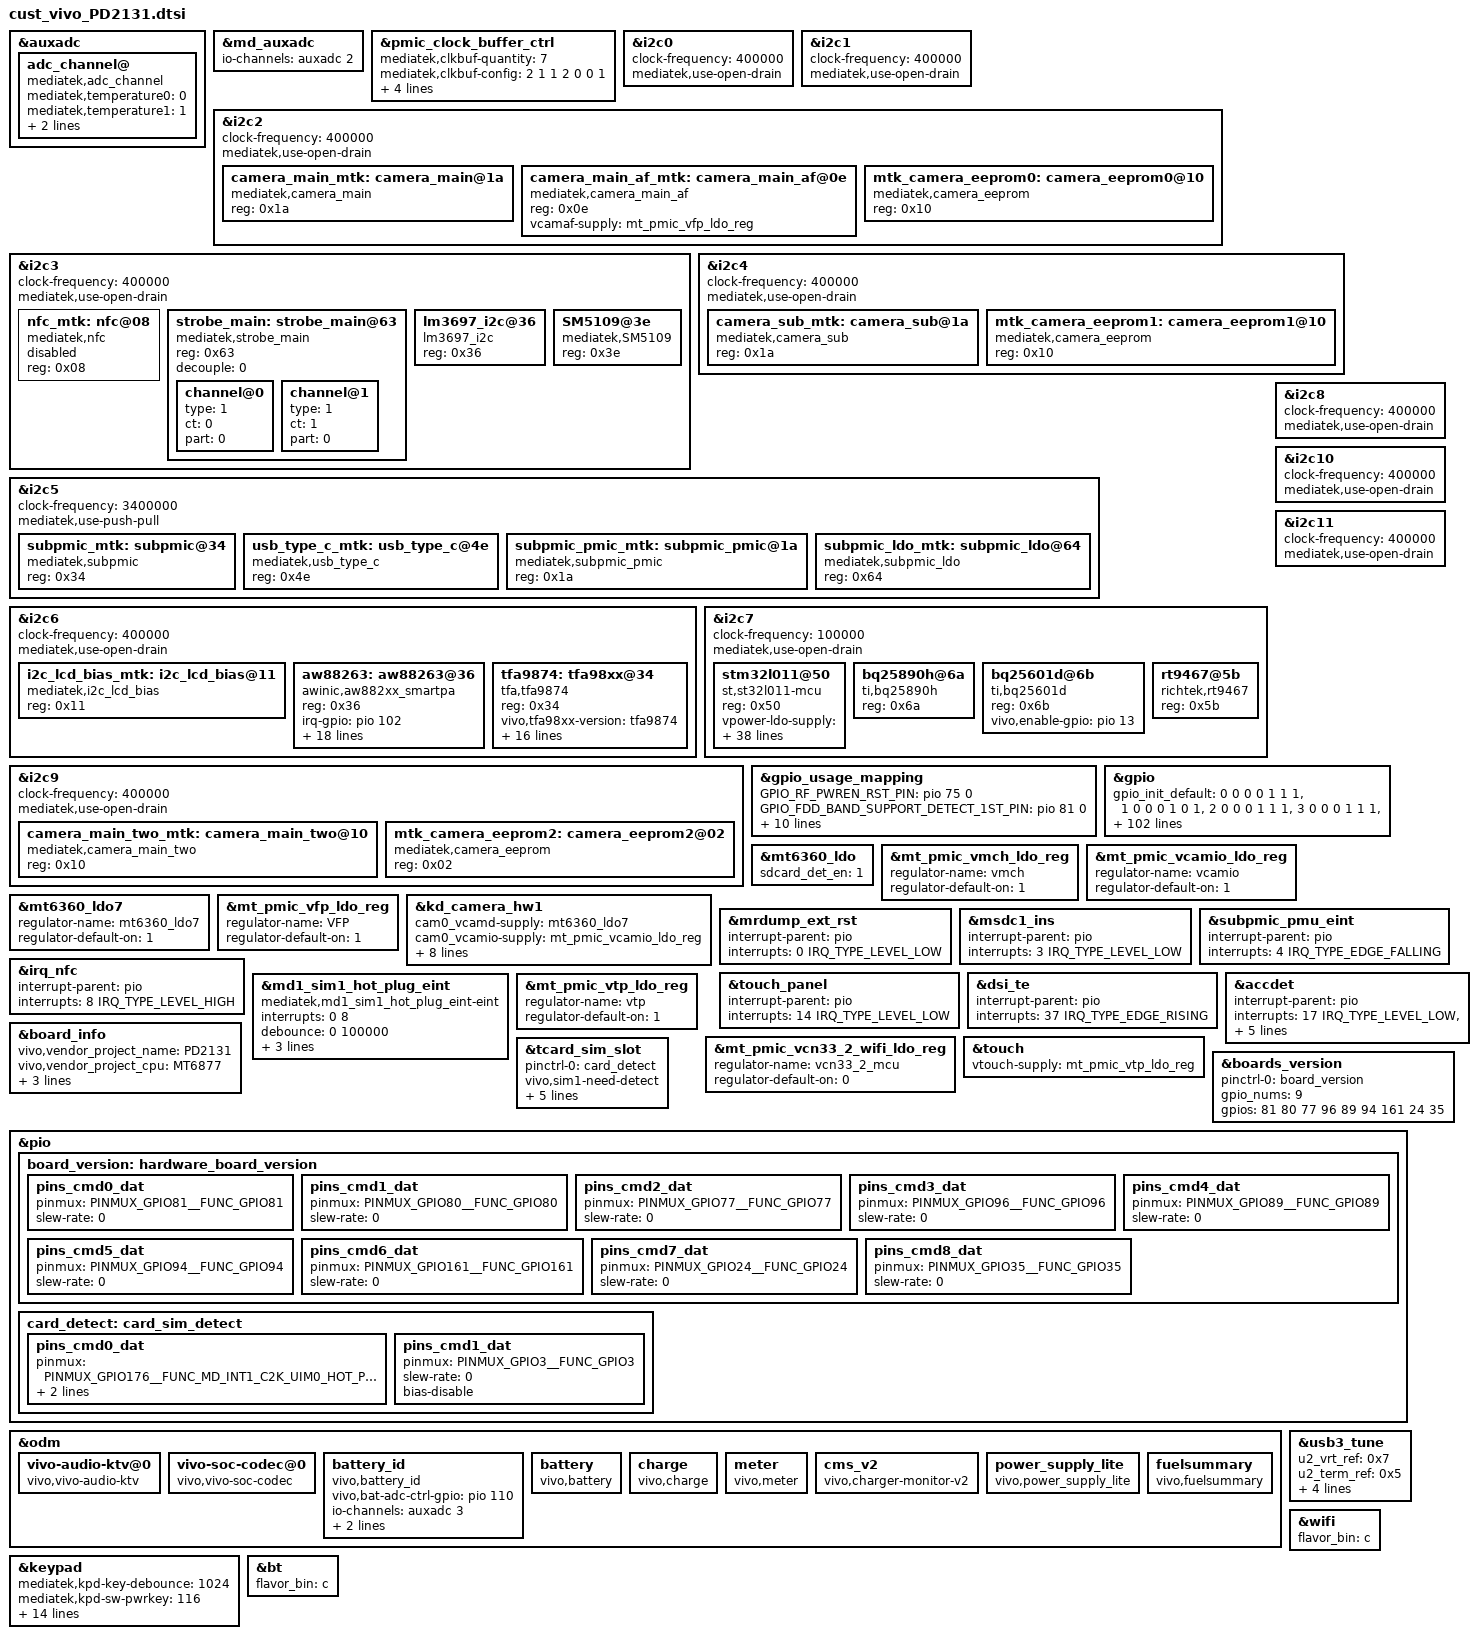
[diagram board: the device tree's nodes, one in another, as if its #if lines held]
/*
 * Generated by MTK SP DrvGen Version: 3.5.160809 for MT6877.
 * 2021-08-30 17:19:41
 * Do Not Modify The File.
 * Copyright Mediatek Inc. (c) 2016.
*/

/*************************
 * ADC DTSI File
*************************/

&auxadc {
	adc_channel@ {
		compatible = "mediatek,adc_channel";
		mediatek,temperature0 = <0>;
		mediatek,temperature1 = <1>;
		mediatek,adc_fdd_rf_params_dynamic_custom_ch = <2>;
		status = "okay";
	};
};
&md_auxadc {
	io-channels = <&auxadc 2>;
};


/*************************
 * CLK_BUF DTSI File
*************************/

&pmic_clock_buffer_ctrl {
	mediatek,clkbuf-quantity = <7>;
	mediatek,clkbuf-config = <2 1 1 2 0 0 1>;
	mediatek,clkbuf-output-impedance = <3 4 3 4 0 0 3>;
	mediatek,clkbuf-controls-for-desense = <0 4 0 4 0 0 0>;
	status = "okay";
};


/*************************
 * I2C DTSI File
*************************/

&i2c0 {
	#address-cells = <1>;
	#size-cells = <0>;
	clock-frequency = <400000>;
	mediatek,use-open-drain;
};

&i2c1 {
	#address-cells = <1>;
	#size-cells = <0>;
	clock-frequency = <400000>;
	mediatek,use-open-drain;
};

&i2c2 {
	#address-cells = <1>;
	#size-cells = <0>;
	clock-frequency = <400000>;
	mediatek,use-open-drain;
	camera_main_mtk:camera_main@1a {
		compatible = "mediatek,camera_main";
		reg = <0x1a>;
		status = "okay";
	};

	camera_main_af_mtk:camera_main_af@0e {
		compatible = "mediatek,camera_main_af";
		reg = <0x0e>;
		status = "okay";
	};
	mtk_camera_eeprom0:camera_eeprom0@10 {
		compatible = "mediatek,camera_eeprom";
		reg = <0x10>;
		status = "okay";
	};

};

&i2c3 {
	#address-cells = <1>;
	#size-cells = <0>;
	clock-frequency = <400000>;
	mediatek,use-open-drain;
	nfc_mtk:nfc@08 {
		compatible = "mediatek,nfc";
		reg = <0x08>;
		status = "disabled";
	};

	/*hope add for flashlight i2c device start*/
	strobe_main: strobe_main@63 {
		compatible = "mediatek,strobe_main";
		reg = <0x63>;
		status = "okay";
	};
	/*hope add for flashlight i2c device end*/

	lm3697_i2c@36 {
		compatible = "lm3697_i2c";
		reg = <0x36>;
		status = "okay";
	};
	SM5109@3e {
		compatible = "mediatek,SM5109";
		reg = <0x3e>;
		status = "okay";
	};
};

&i2c4 {
	#address-cells = <1>;
	#size-cells = <0>;
	clock-frequency = <400000>;
	mediatek,use-open-drain;
	camera_sub_mtk:camera_sub@1a {
		compatible = "mediatek,camera_sub";
		reg = <0x1a>;
		status = "okay";
	};

	mtk_camera_eeprom1:camera_eeprom1@10 {
		compatible = "mediatek,camera_eeprom";
		reg = <0x10>;
		status = "okay";
	};

};

&i2c5 {
	#address-cells = <1>;
	#size-cells = <0>;
	clock-frequency = <3400000>;
	mediatek,use-push-pull;
	subpmic_mtk:subpmic@34 {
		compatible = "mediatek,subpmic";
		reg = <0x34>;
		status = "okay";
	};

	usb_type_c_mtk:usb_type_c@4e {
		compatible = "mediatek,usb_type_c";
		reg = <0x4e>;
		status = "okay";
	};

	subpmic_pmic_mtk:subpmic_pmic@1a {
		compatible = "mediatek,subpmic_pmic";
		reg = <0x1a>;
		status = "okay";
	};

	subpmic_ldo_mtk:subpmic_ldo@64 {
		compatible = "mediatek,subpmic_ldo";
		reg = <0x64>;
		status = "okay";
	};

};

&i2c6 {
	#address-cells = <1>;
	#size-cells = <0>;
	clock-frequency = <400000>;
	mediatek,use-open-drain;
	i2c_lcd_bias_mtk:i2c_lcd_bias@11 {
		compatible = "mediatek,i2c_lcd_bias";
		reg = <0x11>;
		status = "okay";
	};

};

&i2c7 {
	#address-cells = <1>;
	#size-cells = <0>;
	clock-frequency = <400000>;
	mediatek,use-open-drain;
};

&i2c8 {
	#address-cells = <1>;
	#size-cells = <0>;
	clock-frequency = <400000>;
	mediatek,use-open-drain;
};

&i2c9 {
	#address-cells = <1>;
	#size-cells = <0>;
	clock-frequency = <400000>;
	mediatek,use-open-drain;

	camera_main_two_mtk:camera_main_two@10 {
		compatible = "mediatek,camera_main_two";
		reg = <0x10>;
		status = "okay";
	};
	mtk_camera_eeprom2:camera_eeprom2@02 {
		compatible = "mediatek,camera_eeprom";
		reg = <0x02>;
		status = "okay";
	};
};

&i2c10 {
	#address-cells = <1>;
	#size-cells = <0>;
	clock-frequency = <400000>;
	mediatek,use-open-drain;
};

&i2c11 {
	#address-cells = <1>;
	#size-cells = <0>;
	clock-frequency = <400000>;
	mediatek,use-open-drain;
};



/*************************
 * GPIO DTSI File
*************************/

&gpio_usage_mapping {
	GPIO_RF_PWREN_RST_PIN = <&pio 75 0>;
	GPIO_FDD_BAND_SUPPORT_DETECT_1ST_PIN = <&pio 81 0>;
	GPIO_FDD_BAND_SUPPORT_DETECT_2ND_PIN = <&pio 89 0>;
	GPIO_FDD_BAND_SUPPORT_DETECT_3RD_PIN = <&pio 161 0>;
	GPIO_SIM2_SIO = <&pio 170 0>;
	GPIO_SIM2_SCLK = <&pio 171 0>;
	GPIO_SIM2_SRST = <&pio 172 0>;
	GPIO_SIM1_SRST = <&pio 173 0>;
	GPIO_SIM1_SCLK = <&pio 174 0>;
	GPIO_SIM1_SIO = <&pio 175 0>;
	GPIO_SIM1_HOT_PLUG = <&pio 176 0>;
};

&gpio{
	gpio_init_default = <0 0 0 0 1 1 1>,
		<1 0 0 0 1 0 1>,
		<2 0 0 0 1 1 1>,
		<3 0 0 0 1 1 1>,
		<4 0 0 0 1 1 1>,
		<5 0 0 0 1 1 1>,
		<6 0 0 0 0 0 1>,
		<7 0 0 0 1 1 0>,
		<8 0 0 0 1 1 0>,
		<9 0 0 0 1 1 0>,
		<10 0 1 0 1 0 1>,
		<11 0 0 0 1 0 0>,
		<12 2 0 0 1 1 0>,
		<13 0 1 1 1 0 0>,
		<14 0 0 0 1 1 1>,
		<15 0 1 0 1 0 1>,
		<16 7 0 0 1 1 0>,
		<17 7 0 0 1 1 0>,
		<18 0 1 0 0 0 0>,
		<19 0 1 0 0 0 0>,
		<20 7 0 0 0 0 0>,
		<21 0 1 0 1 0 0>,
		<22 0 1 0 1 0 0>,
		<23 7 0 0 1 1 0>,
		<24 0 0 0 1 1 0>,
		<25 1 0 0 0 0 0>,
		<26 1 0 0 1 1 0>,
		<27 1 0 0 0 0 0>,
		<28 0 0 0 0 0 1>,
		<29 0 0 0 0 0 1>,
		<30 0 0 0 0 0 1>,
		<31 0 0 0 0 0 1>,
		<32 1 0 0 1 1 0>,
		<33 1 0 0 1 1 0>,
		<34 1 0 0 1 1 0>,
		<35 0 0 0 1 1 0>,
		<36 1 0 0 1 1 1>,
		<37 1 0 0 1 1 1>,
		<38 1 0 0 1 1 1>,
		<39 1 0 0 1 0 1>,
		<40 0 1 0 1 0 1>,
		<41 1 0 0 0 0 1>,
		<42 1 0 0 0 0 1>,
		<43 1 0 0 1 0 1>,
		<44 1 0 0 1 0 1>,
		<45 1 0 0 1 1 1>,
		<46 1 0 0 0 0 0>,
		<47 1 0 0 0 0 0>,
		<48 1 0 0 0 0 0>,
		<49 1 0 0 0 0 0>,
		<50 1 0 0 1 0 0>,
		<51 1 0 0 1 0 0>,
		<52 1 0 0 1 0 0>,
		<53 1 0 0 1 0 0>,
		<54 1 0 0 1 0 1>,
		<55 1 0 0 1 0 0>,
		<56 1 0 0 1 0 0>,
		<57 1 0 0 1 0 0>,
		<58 1 0 0 1 0 0>,
		<59 1 0 0 1 0 0>,
		<60 1 0 0 0 0 1>,
		<61 1 0 0 0 0 1>,
		<62 1 0 0 0 0 1>,
		<63 1 0 0 0 0 1>,
		<64 1 0 0 1 1 1>,
		<65 1 0 0 1 1 1>,
		<66 1 0 0 1 0 1>,
		<67 1 0 0 1 0 1>,
		<68 1 0 0 0 0 0>,
		<69 1 0 0 1 0 0>,
		<70 1 0 0 1 0 1>,
		<71 1 0 0 0 0 1>,
		<72 1 0 0 0 0 1>,
		<73 1 0 0 0 0 1>,
		<74 1 0 0 0 0 1>,
		<75 0 1 1 1 0 1>,
		<76 1 0 0 0 0 1>,
		<77 0 0 0 1 1 0>,
		<78 1 0 0 0 0 1>,
		<79 1 0 0 0 0 1>,
		<80 0 0 0 1 1 0>,
		<81 0 0 0 1 1 0>,
		<82 1 0 0 0 0 0>,
		<83 1 0 0 1 0 0>,
		<84 1 0 0 0 0 0>,
		<85 1 0 0 1 0 0>,
		<86 1 0 0 1 0 1>,
		<87 1 0 0 0 0 1>,
		<88 1 0 0 0 0 1>,
		<89 0 0 0 1 1 0>,
		<90 1 0 0 0 0 1>,
		<91 1 0 0 0 0 1>,
		<92 1 0 0 0 0 1>,
		<93 1 0 0 0 0 1>,
		<94 0 0 0 1 1 0>,
		<95 1 0 0 0 0 1>,
		<96 0 0 0 1 1 0>,
		<97 1 0 0 0 0 1>,
		<98 0 1 0 0 0 1>,
		<99 0 1 0 0 0 1>,
		<100 0 1 0 0 0 1>,
		<101 0 1 0 0 0 1>,
		<102 1 0 0 1 1 0>,
		<103 1 0 0 1 1 0>,
		<104 1 0 0 1 1 0>,
		<105 1 0 0 1 1 0>,
		<106 1 0 0 1 1 0>,
		<107 0 1 1 1 0 1>,
		<108 0 1 0 1 0 1>,
		<109 0 1 0 1 0 0>,
		<110 0 1 0 1 0 0>,
		<111 0 1 0 1 0 0>,
		<112 1 0 0 1 1 0>,
		<113 0 0 0 1 1 0>,
		<114 0 0 0 1 1 0>,
		<115 0 1 1 1 0 0>,
		<116 1 0 0 1 1 1>,
		<117 0 0 0 1 1 0>,
		<118 0 0 0 1 1 0>,
		<119 0 0 0 1 1 0>,
		<120 1 0 0 1 1 0>,
		<121 0 0 0 1 1 0>,
		<122 7 0 0 1 1 1>,
		<123 7 0 0 1 1 0>,
		<124 7 0 0 1 1 0>,
		<125 7 0 0 1 1 0>,
		<126 2 0 0 1 0 0>,
		<127 2 0 0 1 0 0>,
		<128 2 0 0 1 1 1>,
		<129 2 0 0 1 0 1>,
		<130 2 0 0 1 1 1>,
		<131 2 0 0 1 1 1>,
		<132 1 0 0 1 1 1>,
		<133 1 0 0 1 1 1>,
		<134 1 0 0 1 1 1>,
		<135 1 0 0 1 1 1>,
		<136 1 0 0 1 1 1>,
		<137 1 0 0 1 1 1>,
		<138 4 0 0 1 1 0>,
		<139 4 0 0 1 1 0>,
		<140 0 1 0 1 0 1>,
		<141 0 1 0 1 0 1>,
		<142 0 1 0 1 0 0>,
		<143 1 0 0 1 1 1>,
		<144 1 0 0 1 1 1>,
		<145 1 0 0 1 1 1>,
		<146 1 0 0 1 1 1>,
		<147 1 0 0 1 1 1>,
		<148 1 0 0 1 1 1>,
		<149 0 1 0 0 0 0>,
		<150 0 1 0 0 0 0>,
		<151 1 0 0 1 1 0>,
		<152 0 1 0 0 0 0>,
		<153 0 0 0 1 1 0>,
		<154 0 1 0 0 0 0>,
		<155 0 1 0 0 0 0>,
		<156 0 0 0 1 1 0>,
		<157 0 1 0 0 0 0>,
		<158 0 0 0 1 1 0>,
		<159 0 0 0 1 1 0>,
		<160 0 1 0 0 0 0>,
		<161 0 0 0 1 1 0>,
		<162 0 0 0 1 1 0>,
		<163 0 1 0 0 0 0>,
		<164 1 0 0 1 1 0>,
		<165 1 0 0 0 0 0>,
		<166 1 0 0 1 1 0>,
		<167 1 0 0 1 1 0>,
		<168 1 0 0 1 1 0>,
		<169 1 0 0 1 1 0>,
		<170 1 0 0 1 1 1>,
		<171 1 0 0 0 0 1>,
		<172 1 0 0 0 0 1>,
		<173 1 0 0 0 0 1>,
		<174 1 0 0 0 0 1>,
		<175 1 0 0 1 1 1>,
		<176 1 0 0 0 0 1>,
		<177 0 0 0 0 0 1>,
		<178 1 0 0 1 0 0>,
		<179 1 0 0 1 0 0>,
		<180 1 0 0 1 1 1>,
		<181 1 0 0 1 1 1>,
		<182 1 0 0 1 1 0>,
		<183 1 0 0 1 1 0>,
		<184 1 0 0 0 0 0>,
		<185 1 0 0 0 0 0>,
		<186 1 0 0 1 1 1>,
		<187 1 0 0 1 1 1>,
		<188 0 1 0 1 1 0>,
		<189 0 1 0 1 1 0>,
		<190 1 0 0 1 1 0>,
		<191 1 0 0 1 1 0>,
		<192 1 0 0 1 1 0>,
		<193 0 0 0 1 1 0>,
		<194 0 0 0 1 1 0>,
		<195 0 0 0 1 1 0>,
		<196 0 0 0 1 0 0>,
		<197 0 0 0 1 0 0>,
		<198 0 0 0 1 0 0>,
		<199 0 0 0 1 0 0>,
		<200 0 0 0 1 0 0>,
		<201 0 0 0 1 0 0>,
		<202 0 0 0 1 0 0>,
		<203 0 0 0 1 0 0>,
		<204 0 0 0 1 0 0>,
		<205 0 0 0 1 0 0>,
		<206 0 0 0 1 0 0>,
		<207 0 0 0 1 0 0>,
		<208 0 0 0 1 0 0>;
};


/* yangtao add for tf start */
&mt6360_ldo {
	sdcard_det_en = <1>; /* enable tf */
};
/* yangtao add for tf end */

&mt_pmic_vmch_ldo_reg {
	regulator-name = "vmch";
	regulator-default-on = <1>; /* 0:skip, 1: off, 2:on */
	status = "okay";
};

&mt_pmic_vcamio_ldo_reg {
	regulator-name = "vcamio";
	regulator-default-on = <1>; /* 0:skip, 1: off, 2:on */
	status = "okay";
};


&mt6360_ldo7 {
	regulator-name = "mt6360_ldo7";
	regulator-default-on = <1>; /* 0:skip, 1: off, 2:on */
	status = "okay";
};

&mt_pmic_vfp_ldo_reg {
	regulator-name = "VFP";
	regulator-default-on = <1>; /* 0:skip, 1: off, 2:on */
	status = "okay";
};


&kd_camera_hw1 {
	cam0_vcamd-supply = <&mt6360_ldo7>;
	cam0_vcamio-supply = <&mt_pmic_vcamio_ldo_reg>;		
	cam1_vcamio-supply = <&mt_pmic_vcamio_ldo_reg>;
	cam2_vcamio-supply = <&mt_pmic_vcamio_ldo_reg>;
	
	cam0_enable_sensor = "s5kjn1sq03pd2131_mipi_raw s5kgw3sp13pd2123_mipi_raw";
	cam1_enable_sensor = "imx355pd2131_mipi_raw s5k3p9sppd2123_mipi_raw";
        cam2_enable_sensor = "ov02b10pd2131_mipi_raw";
	
	status = "okay";
};


/*lishuo add main af pmic power start*/
&camera_main_af_mtk {
	vcamaf-supply = <&mt_pmic_vfp_ldo_reg>;
};
/*lishuo add main af pmic power end*/


/*hope add for flashlight channel start*/
&strobe_main {
	decouple = <0>;
	channel@0 {
		type = <1>;
		ct = <0>;
		part = <0>;
	};
	channel@1 {
		type = <1>;
		ct = <1>;
		part = <0>;
	};
};
/*hope add for flashlight channel end*/

/*************************
 * EINT DTSI File
*************************/

#include <dt-bindings/interrupt-controller/irq.h>
#include <dt-bindings/interrupt-controller/arm-gic.h>

&mrdump_ext_rst {
	interrupt-parent = <&pio>;
	interrupts = <0 IRQ_TYPE_LEVEL_LOW>;
	status = "okay";
};

&msdc1_ins {
	interrupt-parent = <&pio>;
	interrupts = <3 IRQ_TYPE_LEVEL_LOW>;
	status = "okay";
};

&subpmic_pmu_eint {
	interrupt-parent = <&pio>;
	interrupts = <4 IRQ_TYPE_EDGE_FALLING>;
	status = "okay";
};

&irq_nfc {
	interrupt-parent = <&pio>;
	interrupts = <8 IRQ_TYPE_LEVEL_HIGH>;
	status = "okay";
};

&touch_panel {
	interrupt-parent = <&pio>;
	interrupts = <14 IRQ_TYPE_LEVEL_LOW>;
	status = "okay";
};

&dsi_te {
	interrupt-parent = <&pio>;
	interrupts = <37 IRQ_TYPE_EDGE_RISING>;
	status = "okay";
};

&accdet {
	interrupt-parent = <&pio>;
	interrupts = <17 IRQ_TYPE_LEVEL_LOW>,
					<16 IRQ_TYPE_LEVEL_LOW>;
	deb-gpios = <&pio 17 0>;
	deb-rgpios = <&pio 16 0>;
	debounce = <256000>;
	debounce1 = <256000>;
	status = "okay";
};



/*************************
 * MD1_EINT DTSI File
*************************/

&md1_sim1_hot_plug_eint {
	compatible = "mediatek,md1_sim1_hot_plug_eint-eint";
	interrupts = <0 8>;
	debounce = <0 100000>;
	dedicated = <0 0>;
	src_pin = <0 1>;
	sockettype = <0 0>;
	status = "okay";
};




/*************************
 * PMIC DTSI File
*************************/

&mt_pmic_vcamio_ldo_reg {
	regulator-name = "vcamio";
	regulator-default-on = <1>; /* 0:skip, 1: off, 2:on */
	status = "okay";
};
&mt_pmic_vtp_ldo_reg {
	regulator-name = "vtp";
	regulator-default-on = <1>; /* 0:skip, 1: off, 2:on */
	status = "okay";
};

&kd_camera_hw1 {
	vcamio-supply = <&mt_pmic_vcamio_ldo_reg>;
	status = "okay";
};

&mt_pmic_vcn33_2_wifi_ldo_reg {
	regulator-name = "vcn33_2_mcu";
	regulator-default-on = <0>;
	status = "okay";
};
&touch {
	vtouch-supply = <&mt_pmic_vtp_ldo_reg>;
	status = "okay";
};

/* add board info fdt node by corebsp begin */
&board_info {
	vivo,vendor_project_name = "PD2131";
	vivo,vendor_project_cpu = "MT6877";
	vivo,vendor_cpu_set = "Dimensity_900";
	vivo,vendor_project_freq = "2.4";
	vivo,vendor_project_cpunum = <8>;
};

&boards_version {
	pinctrl-names = "default";
	pinctrl-0 = <&board_version>;
	gpio_nums = <9>;
	gpios = <81 80 77 96 89 94 161 24 35>;
	/* if use pcb version,need to define:pcb_gpio_nums pcb_gpios pcb_maps_nums pcb_gpios_maps */
	/*pcb_gpio_nums = <2>;*/
	/*pcb_gpios = <107 108>;*/
	/* 00:MP_0.1, 01:MP_0.2, 10:MP_0.3, 11:MP_0.4 */
	/*pcb_maps_nums = <8>;*/
	/*pcb_gpios_maps = <0x0 0x1 0x1 0x2 0x2 0x3 0x3 0x4>;*/

};

&tcard_sim_slot {
	pinctrl-names = "default";
	pinctrl-0 = <&card_detect>;
	vivo,sim1-need-detect;
	vivo,sim2-need-detect;
	vivo,sim1-detect-high;
	vivo,sim2-detect-high;

	card-detect-sim1,gpios = <&pio 176 0x0>;
	card-detect-sim2,gpios = <&pio 176 0x0>;
};

&pio {
	board_version: hardware_board_version {
		pins_cmd0_dat {
			pinmux = <PINMUX_GPIO81__FUNC_GPIO81>;
			slew-rate = <0>;
		};
		pins_cmd1_dat {
			pinmux = <PINMUX_GPIO80__FUNC_GPIO80>;
			slew-rate = <0>;
		};
		pins_cmd2_dat {
			pinmux = <PINMUX_GPIO77__FUNC_GPIO77>;
			slew-rate = <0>;
		};
		pins_cmd3_dat {
			pinmux = <PINMUX_GPIO96__FUNC_GPIO96>;
			slew-rate = <0>;
		};
		pins_cmd4_dat {
			pinmux = <PINMUX_GPIO89__FUNC_GPIO89>;
			slew-rate = <0>;
		};
		pins_cmd5_dat {
			pinmux = <PINMUX_GPIO94__FUNC_GPIO94>;
			slew-rate = <0>;
		};
		pins_cmd6_dat {
			pinmux = <PINMUX_GPIO161__FUNC_GPIO161>;
			slew-rate = <0>;
		};
		pins_cmd7_dat {
			pinmux = <PINMUX_GPIO24__FUNC_GPIO24>;
			slew-rate = <0>;
		};
		pins_cmd8_dat {
			pinmux = <PINMUX_GPIO35__FUNC_GPIO35>;
			slew-rate = <0>;
		};
	};

	card_detect: card_sim_detect {
		pins_cmd0_dat {
			pinmux = <PINMUX_GPIO176__FUNC_MD_INT1_C2K_UIM0_HOT_PLUG>;
			slew-rate = <0>;
			bias-disable;
		};
		pins_cmd1_dat {
			pinmux = <PINMUX_GPIO3__FUNC_GPIO3>;
			slew-rate = <0>;
			bias-disable;
		};
	};
};
/* add board info fdt node by corebsp end */


/*************************
 * POWER DTSI File
*************************/



/*************************
 * qinbaoqiang add for audio start
**************************/
&odm {
	vivo-audio-ktv@0 {
		compatible = "vivo,vivo-audio-ktv";
		status = "okay";
	};
	
	vivo-soc-codec@0 {
		compatible = "vivo,vivo-soc-codec";
		status = "okay";
	};
/*	
	typec_switch:typecswitch {
		compatible = "vivo,typec-switch";
		interrupt-parent = <&pio>;
		interrupts = <17 IRQ_TYPE_LEVEL_LOW 17 0>;
		deb-gpios = <&pio 17 0>;
		debounce = <256000>;
		pinctrl-names = "default", "typec_eint_as_int";
		pinctrl-0 = <&typec_pins_default>;
		pinctrl-1 = <&typec_eint_as_int>;
		status = "okay";
	};	*/
};
/*
&pio {
	typec_pins_default: typecdefault {
	};
	typec_eint_as_int: typeceint@0 {
		pins_cmd_dat {
			pinmux = <PINMUX_GPIO17__FUNC_GPIO17>;
			slew-rate = <0>;
			bias-pull-up;
			input-enable;
		};
	};
};*/

&i2c6{
/*
	tas2562:tas2562@4c {
		compatible = "ti,tas2562";
		reg = <0x4c>;
		ti,left-channel = <0x4c>;
		ti,channels = <1>; *//* channel number */
/*		ti,reset-gpio = <&pio 111 0>;
		ti,irq-gpio = <&pio 102 0>;

		vivo,impedance-min = <3145728>;*/ /*speaker min impedance 6.0ohm*/
/*		vivo,impedance-max = <5242880>; *//*speaker max impedance 10.0ohm*/
/*		vivo,frequency-min = <400>;
		vivo,frequency-max = <920>;
		vivo,Qt-min = <100>;
		status = "okay";
    };
*/
	aw88263:aw88263@36 {
		/* AWINIC AW88263 mono SmartPA */
		compatible = "awinic,aw882xx_smartpa";
		reg = <0x36>;
		irq-gpio = <&pio 102 0>;
		reset-gpio = <&pio 111 0>;
		monitor-flag = <1>;

		/*archer fix for replace aw protection algorithm with vivo algorithm,because vivo algorithm will read smartamp.bin,but it's awinic ctreate*/
		vivo-replace-protect-algo;

		aw-cali-mode = "aw_debugfs"; //aw_misc or aw_debugfs
		vivo,impedance-min = <2621440>; /*speaker min impedance 5.0ohm*/
		vivo,impedance-max = <5242880>; /*speaker max impedance 10.0ohm*/
		vivo,frequency-min = <500>;
		vivo,frequency-max = <950>;
		vivo,Qt-min = <110>;

		vivo,Impedance-Min-L15 = <163840>; /* 5*2^15 */
		vivo,Impedance-Max-L15 = <327680>; /* 10*2^15 */
		vivo,Frequency-Min-L15 = <16384000>; /* 500*2^15 */
		vivo,Frequency-Max-L15 = <32768000>; /* 1000*2^15 */
		vivo,Qt-Min-L15 = <32768>;  /* 1*2^15 */
		vivo,VendorID = <63>;       /* AW88263 */
		vivo,V-Max-L15 = <589824>;  /* 18*2^15 */
		vivo,I-Max-L15 = <120259>;  /* 3.67*2^15 */
		vivo,Vout-Max-L15 = <262144>; /* 8*2^15 */

		status = "okay";
	};
	tfa9874: tfa98xx@34 {
		status = "okay";
		compatible = "tfa,tfa9874";
		#sound-dai-cells = <1>;
		reg = <0x34>;
		vivo,tfa98xx-version = "tfa9874";
		vivo,tfa98xx-config = "tfa98xx_PD2131.cnt";
		vivo,tfa98xx-impedance-min = <6000>;
		vivo,tfa98xx-impedance-max = <10000>;
		vivo,tfa98xx-frequency-min = <600>;
		vivo,tfa98xx-frequency-max = <900>;
		vivo,tfa98xx-Qt-min = <110>;
		reset-gpio = <&pio 111 0>;

		vivo,Impedance-Min-L15 = <163840>; /* 5*2^15 */
		vivo,Impedance-Max-L15 = <327680>; /* 10*2^15 */
		vivo,Frequency-Min-L15 = <16384000>; /* 500*2^15 */
		vivo,Frequency-Max-L15 = <32768000>; /* 1000*2^15 */
		vivo,Qt-Min-L15 = <32768>;  /* 1*2^15 */
		vivo,VendorID = <74>;       /* NXP9874 */
		vivo,V-Max-L15 = <747111>;  /* 22.8*2^15 */
		vivo,I-Max-L15 = <109118>;  /* 3.33*2^15 */
		vivo,Vout-Max-L15 = <327680>; /* 10*2^15 */
	};
};
/*  qinbaoqiang add end */

/*
	{TI_SMART_PA, (14<<15)458752, (2<<15)65536, 260506}
	{NXP_SMART_PA, 747111, 109118, 327680}
	{AW_SMART_PA, (18<<15), 120259, 262144}
*/

/* fuxi add for battery&charge start */
#ifdef CONFIG_VIVO_CHARGING_NEW_ARCH
#ifdef CONFIG_VIVO_CHARGING_DTS_MOVE_HEAD_FILE
&odm {
	battery_id {
		compatible = "vivo,battery_id";
		status = "okay";

		vivo,bat-adc-ctrl-gpio = <&pio 110 0>;

		io-channels = <&auxadc 3>;
		io-channel-names = "battery_id_adc";

		vivo,bat-name = "B-N8 ATL 3920","B-G7 SX 5000","B-G7 ATL 5000","UNKNOWN";
	};

	battery: battery {
		compatible = "vivo,battery";
		status = "okay";
	};

	charge: charge {
		compatible = "vivo,charge";
		status = "okay";
	};

	meter: meter {
		compatible = "vivo,meter";
		status = "okay";
	};

	cms_v2: cms_v2 {
		compatible = "vivo,charger-monitor-v2";
		status = "okay";
	};

	power_supply_lite: power_supply_lite {
		compatible = "vivo,power_supply_lite";
		status = "okay";
	};

	fuelsummary: fuelsummary {
		compatible = "vivo,fuelsummary";
		status = "okay";
	};
};

#else

&battery_id {
	status = "okay";
	compatible = "vivo,battery_id";

	vivo,bat-adc-ctrl-gpio = <&pio 110 0>;

	io-channels = <&auxadc 3>;
	io-channel-names = "battery_id_adc";

	vivo,bat-name = "UNKNOWN","B-R3 AT DS 5000","B-Q7 AT NV 5000";
};

&battery {
	status = "okay";
	compatible = "vivo,battery";

	io-channels = <&auxadc 0>,
		<&auxadc 4>;
	io-channel-names = "primary_board_therm",
		"parallel_board_therm";

	vivo,low-volt-threshold = <3400>;
	vivo,soft-rise-percent = <96>;
	vivo,soft-rise-cumulative = <3>;
	vivo,soft-rise-keep-cumulative = <10>;
	vivo,percnet-sync-delta = <5>;
	vivo,percnet-sync-cumulative = <9>;
	vivo,full-sync-cumulative = <3>;
	vivo,soft-term-percent = <99>;
	vivo,soft-term-cumulative = <36>;
};

&charge {
	status = "okay";
	compatible = "vivo,charge";

	vivo,chg-wdt-s = <40>;
	vivo,re-chg-voltage-mv = <100>;
	vivo,prechg-voltage-mv = <3000>;
	vivo,iprechg-current-ma = <300>;
	vivo,iterm-current-ma = <256>;
	vivo,vreg-voltage-mv = <4430>;
	vivo,vindpm-voltage-mv = <4600>;
	vivo,sys-voltage-min-mv= <3300>;
	vivo,boostv-voltage-mv = <5150>;
	vivo,boostv-ilimit-ma = <1300>;
	vivo,ovp-voltage-mv = <15000>;

	/*
	 * 0  auto detect charging
	 * 1  vivo-normal chargine
	 * 2  vivo-single engine charging
	 * 3  vivo-dual engine charging
	 * 4  vivo-flash charging
	 */
	vivo,charge-scheme = <0>;
	vivo,direct-charger-enable;

	/*
	 * SUPPORTED_ADAPTER_DEFAULT = 0,
	 * SUPPORTED_ADAPTER_VIVO_LV_DCHG_5V_4500MA = 1,
	 * SUPPORTED_ADAPTER_VIVO_HV_DCHG_10V_2250MA = 2,
	 * SUPPORTED_ADAPTER_QC20__9V_2000MA = 3,
	 * SUPPORTED_ADAPTER_VIVO_HV_DCHG_10V_4000MA = 4,
	 * SUPPORTED_ADAPTER_MAX,
	 */
	vivo,supported-adapter = <3>;

	//parameter for 9V2A
	vivo,primary-ichg-max-ma = <2240>;
	vivo,parallel-ichg-max-ma = <1680>;

	vivo,flashchg-spec-ma = <2000 4500 8200>;
	vivo,fastchg-spec-ma = <2000 2100 3800>;
	vivo,normalchg-spec-ma = <2000 1500 2300>;

	/* 0---PMIC; 1---CHGIC */
	vivo,vbus-detect-source = <1>;

	//vivo,usboe-gpio = <&pio 163 0>;

	/*ffc*/
	//vivo,ffc-enable;
	vivo,ffc-iterm-ma = <(-750)>;
	vivo,ffc-vreg-mv = <4500>;
	vivo,ffc-temperature-range = <150 450>;
	vivo,ffc-full-vbat-table-size = <3>;
	vivo,ffc-full-vbat-table = <4480 4480 4440>;
	vivo,ffc-full-ibat-table-size = <3>;
	vivo,ffc-full-ibat-table = <150 199 (-858)>,
		<200 349 (-1127)>,
		<350 449 (-1274)>;
};

&meter {
	status = "okay";
	compatible = "vivo,meter";

	vivo,load-capacity-delta-max = <60>;
	vivo,poweron-delta-capacity = <20>;
	vivo,poweron-low-capacity = <3>;
	vivo,volt-car-delta = <8>;
	vivo,car-volt-delta = <6>;
	vivo,meter-res-compesate = <10>;
	vivo,ocv-board-compesate = <0>;

	/* 0---AGING_UNSUPPORTED; 1---DRIVER_SUPPORTED; 2---USPACE_SUPPORTED */
	vivo,battery-aging-support = <2>;

	vivo,capacity-mAh = <4880>;
	/*COLD_CHG COLD_DISCHG NORMAL_CHG NORMAL_DISCHG*/
	vivo,car-tune-value = <980 1010 1000 1010>,
		<980 1010 1000 1010>,
		<1000 1000 1000 1000>,
		<1000 1000 1000 1000>,
		<1000 1000 1000 1000>,
		<1000 1000 1000 1000>;
	vivo,bats-qmax = <4060 4280 4400 4640 4750>,
		<4060 4280 4400 4640 4750>,
		<4240 4480 4770 4850 4880>,
		<4611 4630 4747 4805 4786>,
		<4611 4630 4747 4805 4786>,
		<4611 4630 4747 4805 4786>;
	#include "bat_setting/PD2123_battery_table.dtsi"
	/* car-tune adjust remap */
	vivo,car-tune-adjust-enable;
	vivo,car-tune-adjust-size = <3>;
	vivo,car-tune-adjust-table = <0 10 (355) 7>,
		<11 20 (-30) 9>,
		<21 100 (-30) 12>;
};

&cms_v2 {
	compatible = "vivo,charger-monitor-v2";
	status = "okay";

	default_board: single_charger_board {
		       /*default board: keep in xxxxxx*/
		       support-board-version = "xxxxxx";

		       vivo,bat-det-method = <0>;//r:0, rc:1, eprom:2, ex-fg:3
		       vivo,bat-id-gpio = <&pio 110 0>;

		       /*
			  CHG0__CHARGING_TECHNOLOGY_NONE = 0,
			  CHG1__NORMAL_CHARGING,			//5V/2A normal charging
			  CHG2__QC2_CHARGING,				//9V/2A	QC2.0 charging
			  CHG3__LOW_VOLTAGE_DIRECT_CHARGING,		//5V/4.5A direct charging
			  CHG4__SINGLE_IC_DIV2_CHARGING,		//single IC Div/2 charging
			  CHG5__DUAL_IC_DIV2_CHARGING,			//Dual IC Div/2 charging
			  CHG6__DUAL_IC_DUAL_BATTERY_DIV2_CHARGING,	//Dual IC Div/2 charging
			  CHGX__CHARGING_TECHNOLOGY_MAX,
			*/
		       //vivo,charging-technology = <2>;

		       //vivo,no-bat-warning;
		       //vivo,no-chg-timeout;
		       vivo,chg-timeout-mins = <900>;

		       //high temperature charger current control enable
		       vivo,htccc-enable;
		       vivo,htccc-data = <46 55 4100000 100000>;

		       //vivo,fbon-scale-enable;/*disable default*/
		       vivo,fbon-scale-data = <2 100 100>;

		       //vivo,switch-scale-enable;/*disable from rom4.0*/
		       vivo,switch-scale-data = <75 53>;

		       vivo,calling-scale-enable;
		       vivo,calling-scale-data = <100 38>;/*ibat:3900 * 0.54 = 2106,more than 1500,not exit dchg*/
		       vivo,calling-dchg-disable;

		       vivo,weixin-calling-scale-enable;
		       vivo,weixin-calling-scale-data = <100 104>;/*4200mA*/

		       vivo,carlife-scale-enable;
		       vivo,carlife-scale-data = <100 12>;/*500mA*/

		       //vivo,fixed-scale-enable;
		       vivo,fixed-scale-data = <120 3800 0>;/*dchg fixed time adjust the max ibat,disable default*/

		       /*data processing : batt-temp*/
		       vivo,dp-batt-temp-enable;
		       vivo,dp-batt-temp-data = <100>;

		       vivo,vbat-r-comp = <12>;

		       /* charging current for devices in exhibition mode */
		       vivo,exhibition-mode-current-primary = <2048>;
		       vivo,exhibition-mode-current-parallel = <0>;

		       /*default tc parameter*/
		       //single charger ibat scale base on temperature battery cell info:1C/1.2C 3960mah
		       /* tmin, tmax, data, volt1, data_ex1, volt2, data_ex2. */
		       vivo,normal-tc-row-col = <10 9>;
		       vivo,normal-tc-data = <550 8888 0 0 0 0 0 0 0>,
			       <450 549 50 0 0 0 0 0 0>,
			       <200 449 74 0 0 0 0 0 0>,
			       <150 199 74 0 0 0 0 0 0>,
			       <100 149 74 4200000 54 0 0 0 0>,
			       <50 99 54 0 0 0 0 0 0>,
			       <0 49 54 0 0 0 0 0 0>,
			       <(-8888) (-1) 0 0 0 0 0 0 0>,
			       <(-8888) (-1) 0 0 0 0 0 0 0>,
			       <(-8888) (-1) 0 0 0 0 0 0 0>;

		       /*flash tc parameter*/
		       vivo,flash-normal-tc-row-col = <11 9>;
		       vivo,flash-normal-tc-data = <550 8888 0 0 0 0 0 0 0>,
			       <450 549 60 0 0 0 0 0 0>,
			       <350 449 164 4200000 123 4430000 82 0 0>,
			       <200 349 164 4200000 123 4430000 82 0 0>,
			       <150 199 150 4200000 120 4430000 80 0 0>,
			       <100 149 100 0 0 0 0 0 0>,
			       <50 99 70 4200000 50 0 0 0 0>,
			       <0 49 70 4200000 50 0 0 0 0>,
			       <(-50) (-1) 0 0 0 0 0 0 0>,
			       <(-100) (-51) 0 0 0 0 0 0 0>,
			       <(-8888) (-101) 0 0 0 0 0 0 0>;

		       /*adjust fastchg base on board temperature and fb off*/
		       vivo,intell-charge-enable;
		       vivo,parallel-temp-enable = <1 1>;//<x y> x:fb-on y:fb-off

		       /* Flash charge fb-on intell param */
		       vivo,primary-fbon-tc-row-col = <7 3>;
		       vivo,primary-fbon-tc-data = <476 8888 1500>,
			       <461 475 2000>,
			       <451 460 2500>,
			       <421 450 3500>,
			       <391 420 4900>,
			       <381 390 6500>,
			       <(-8888) 380 8000>;

		       vivo,parallel-fbon-tc-row-col = <1 3>;
		       vivo,parallel-fbon-tc-data = <(-8888) 8888 0>;

		       /* Flash charge fb-off intell param */
		       vivo,primary-fboff-tc-row-col = <7 3>;
		       vivo,primary-fboff-tc-data = <460 8888 1800>,
			       <440 459 2700>,
			       <425 439 3900>,
			       <400 424 4700>,
			       <385 399 5600>,
			       <370 384 6400>,
			       <(-8888) 369 8000>;
		       vivo,parallel-fboff-tc-row-col = <1 3>;
		       vivo,parallel-fboff-tc-data = <(-8888) 8888 0>;

		       /* 9v Fast charge fb-on intell param */
		       vivo,9v-primary-fbon-tc-row-col = <7 3>;
		       vivo,9v-primary-fbon-tc-data = <451 8888 500>,
			       <441 450 700>,
			       <421 440 1200>,
			       <401 420 1300>,
			       <391 400 1600>,
			       <371 390 1800>,
			       <(-8888) 370 2100>;
		       vivo,9v-parallel-fbon-tc-row-col = <6 3>;
		       vivo,9v-parallel-fbon-tc-data = <441 8888 300>,
			       <421 440 500>,
			       <381 420 600>,
			       <371 380 1000>,
			       <351 370 1300>,
			       <(-8888) 350 1500>;
		       // second parallel parameter, for rt9467
		       vivo,9v-2nd-parallel-fbon-tc-row-col = <6 3>;
		       vivo,9v-2nd-parallel-fbon-tc-data = <441 8888 300>,
			       <421 440 500>,
			       <381 420 600>,
			       <371 380 1000>,
			       <351 370 1300>,
			       <(-8888) 350 1500>;
		       /* 9v Fast charge fb-off intell param */
		       vivo,9v-primary-fboff-tc-row-col = <7 3>;
		       vivo,9v-primary-fboff-tc-data = <461 8888 500>,
			       <441 460 1000>,
			       <421 440 1300>,
			       <406 420 1400>,
			       <391 405 1700>,
			       <381 390 1800>,
			       <(-8888) 380 2100>;
		       vivo,9v-parallel-fboff-tc-row-col = <7 3>;
		       vivo,9v-parallel-fboff-tc-data = <441 8888 512>,
			       <421 440 700>,
			       <401 420 900>,
			       <381 400 1100>,
			       <371 380 1200>,
			       <361 370 1300>,
			       <(-8888) 360 1500>;
		       // second parallel parameter, for rt9467
		       vivo,9v-2nd-parallel-fboff-tc-row-col = <7 3>;
		       vivo,9v-2nd-parallel-fboff-tc-data = <441 8888 512>,
			       <421 440 700>,
			       <401 420 900>,
			       <381 400 1100>,
			       <371 380 1200>,
			       <361 370 1300>,
			       <(-8888) 360 1500>;

		       /* 5v Normal charge fb-on intell param */
		       vivo,5v-primary-fbon-tc-row-col = <7 3>;
		       vivo,5v-primary-fbon-tc-data = <491 8888 512>,
			       <471 490 1024>,
			       <451 470 1216>,
			       <431 450 1408>,
			       <411 430 1600>,
			       <381 410 1800>,
			       <(-8888) 380 2048>;
		       vivo,5v-parallel-fbon-tc-row-col = <1 3>;
		       vivo,5v-parallel-fbon-tc-data = <(-8888) 8888 0>;

		       /* 5v Normal charge fb-off intell param */
		       vivo,5v-primary-fboff-tc-row-col = <6 3>;
		       vivo,5v-primary-fboff-tc-data = <491 8888 512>,
			       <471 490 1024>,
			       <451 470 1216>,
			       <431 450 1600>,
			       <411 430 1800>,
			       <(-8888) 410 2304>;
		       vivo,5v-parallel-fboff-tc-row-col = <1 3>;
		       vivo,5v-parallel-fboff-tc-data = <(-8888) 8888 0>;

		       // Direct charging param
		       vivo,direct-charger-enable;//porting_check
		       vivo,ex-bms-psy-name = "bq_bms";

		       // bat_baord, usb_conn, pcb_conn(master_bat_conn), bat_conn
		       vivo,dchg-ntc-protect-enable;
		       vivo,dchg-ntc-protect-data = <750 800 850 850>;

		       vivo,adapter-cooldown-data = <900 850 3400>;
		       /*adapter power derate*/
		       vivo,adapter-power-derate-enable;

		       /* usb connecter protect param
			* USB_PROTECT_NONE = 0,
			* USB_CONN_TEMP_HEAT_PROTECT = BIT(0),
			* USB_ID_PROTECT = BIT(1),
			*/
		       vivo,usb-connecter-protect-enable = <1>;
		       vivo,usb-id-protect-data= <1100 1547 500>;/* 500K, 2M, fcc */
		       vivo,usb-conn-heat-protect-data-row-col = <2 4>;
		       vivo,usb-conn-heat-protect-data= <260 8888 670 620>,
			       <(-8888) 259 570 520>;

		       /*
			* max vbus of adapter:11v, max ibus of adapter:5A
			* min voltage of battery for half chg:3500mV,max voltage of battery for half charge:4100mV,
			* 5V2A charge min current threshold: 1000mA,5V2A charge max current threshold:2100mA,
			* flash charge min current threshold:5000mA,flash charge max current threshold:11000mA
			*/

		       /*default parameter*/
		       vivo,charge-param-judge-threshold = <9 2 3500 4300 1000 2300 2100 3800>;
		       /* factory mode charging test param */
		       vivo,charge-test-param-row-col = <12 3>;
		       vivo,charge-test-param-data = <0 0 5500>, /* cable resistance, min value, max value */
			       <0 0 5500>, /* master ibus, min ibus, max ibus */
			       <0 0 5500>, /* slave ibus, min ibus, max ibus */
			       <1 20 40>, /* batt therm ntc, min value, max value */
			       <1 20 45>, /* board therm ntc, min value, max value */
			       <1 20 50>, /* sub charger ntc, min value, max value */
			       <0 20 45>, /* usb con ntc, min value, max value */
			       <0 20 45>, /* usb con 1 ntc, double usb NTC, min value, max value */
			       <0 20 45>, /* bat btb master ntc, min value, max value */
			       <0 20 50>, /* bat btb sub ntc, min value, max value */
			       <0 20 50>, /* bat board ntc, min value, max value */
			       <0 20 50>; /* wireless charge coil ntc, min value, max value */

		       /*flash parameter*/
		       vivo,flash-charge-param-judge-threshold = <11 4 3500 4100 1000 2300 4500 8200>;
		       /* factory mode charging test param */
		       vivo,flash-charge-test-param-row-col = <12 3>;
		       vivo,flash-charge-test-param-data = <1 0 5500>, /* cable resistance, min value, max value */
			       <1 0 5500>, /* master ibus, min ibus, max ibus */
			       <0 0 5500>, /* slave ibus, min ibus, max ibus */
			       <1 20 40>, /* batt therm ntc, min value, max value */
			       <1 20 45>, /* board therm ntc, min value, max value */
			       <0 20 50>, /* sub charger ntc, min value, max value */
			       <1 20 45>, /* usb con ntc, min value, max value */
			       <0 20 45>, /* usb con 1 ntc, double usb NTC, min value, max value */
			       <1 20 45>, /* bat btb master ntc, min value, max value */
			       <0 20 50>, /* bat btb sub ntc, min value, max value */
			       <1 20 50>, /* bat board ntc, min value, max value */
			       <0 20 50>; /* wireless charge coil ntc, min value, max value */
			#include "bat_setting/PD2123_battery_chg_params.dtsi"
	       };
};

&power_supply_lite {
	status = "okay";
	compatible = "vivo,power_supply_lite";
};

&fuelsummary {
	status = "okay";
	compatible = "vivo,fuelsummary";

	/************************************************************
	 *
	 *  0   vivo-fastchg
	 *  1   qcom-dualchg
	 *  2   mtk-dualchg
	 *  3   qcom-normchg
	 *  4   mtk-normchg
	 *
	 ***********************************************************/
	chg-scheme = <2>;
	fex-version = <3>;
	fbon-ibat = <(-900)>;
	fboff-ibat = <(-1000)>;

	/* 0---AGING_UNSUPPORTED; 1---DRIVER_SUPPORTED; 2---USPACE_SUPPORTED */
	vivo,battery-aging-support = <2>;
};

#endif
&i2c7 {
	#address-cells = <1>;
	#size-cells = <0>;
	status = "okay";
	clock-frequency = <100000>;

	stm32l011@50 {
		compatible = "st,st32l011-mcu";
		reg = <0x50>;

		vpower-ldo-supply = <&mt_pmic_vcn33_2_wifi_ldo_reg>;
		//vivo,power-gpio = <&pio 18 0>;//ZC_LDO_EN
		vivo,int-gpio = <&pio 6 0>;//MCU_INT_AP
		vivo,usbsel-gpio = <&pio 18 0>;//USB_SW_EN
		vivo,shift-en-gpio = <&pio 10 0>;//SHIFT_EN
		vivo,sbu-pwr-gpio = <&pio 19 0>;
		vivo,chgic-version-gpio = <&pio 94 0>;

		ti,temp-cold-degc = <2>;
		ti,temp-hot-degc = <43>;
		vivo,total-limit-max-ma = <8000>;
		vivo,bigdata-collect-time-limit = <95>;//seconds
		vivo,direct-charger-enable;//porting_check

		/*FFC charge: */
		vivo,ffc-support;
		vivo,ffc-temperature-range = <150 450>;
		//vivo,ffc-param-tuning-enable = <1963>;
		vivo,ffc-cc-to-cv-ibat-thr-rc = <1 3>;
		/*<Tmin Tmax current>*/
		vivo,ffc-cc-to-cv-ibat-thr-table = <150 450 3800>;
		vivo,ffc-dchg-cv-mv-rc = <3 2>;
		/*btb_cv,fg_cv*/
		vivo,ffc-dchg-cv-mv-table = <4430 4430>,/*default*/
			<4507 4507>,/*single_charging*/
			<4500 4480>;/*dual_charging*/

		vivo,cout-int-gpio = <&pio 7 0>;

		vivo,sbu-cable-id-detect-enable;
		//vivo,sbu-detect-rely-usb-switch;

		vivo,bat-board-temp-enable = <1>;
		vivo,usb-conn-temp-enable = <2>;
		vivo,bat-conn-temp-enable = <1>;

		vivo,master-bat-conn-temp-enable = <0>;
		vivo,dchg-exit-ntc-threshold = <700 650 700 700 1200>;

		/* BQ25970_SINGLE_DCHG:
		 * DCHG_SINGLE_TYPE_22P5W = 0,
		 * DCHG_SINGLE_TYPE_33W = 1,
		 * DCHG_SINGLE_TYPE_44W = 2,
		 * BQ25970_DUAL_DCHG:DCHG_DUAL_TYPE_44W = 3,
		 */
		vivo,dchg-supported-type = <1>;
		/*adapter power derate*/
		vivo,adapter-power-derate-enable;

		//vivo,single-charger-enable;
		vivo,adapter-sha-encryption;

		io-channels = <&auxadc 5>,
			<&auxadc 6>;

		io-channel-names = "sbu2_cable_id_adc",
			"sbu1_cable_id_adc";

		/*cable r limit table :
		  <rmin,rmax, dchg_ibus_max, cable_id_type, limit_count>
		  cable_id_type: 0:effective cable id, 1:other(default) cable id
		 */
		vivo,cable-r-limit-table-rc = <9 5>;
		vivo,cable-r-limit-table = <(-8888) 278 4000 0 0>,
			<279 336 3000 0 0>,
			<337 400 2250 0 0>,
			<401 511 1800 0 0>,
			<512 8888 0 0 0>,
			<(-8888) 314 3000 1 0>,
			<315 400 2250 1 0>,
			<401 511 1800 1 0>,
			<512 8888 0 1 0>;

		/*load firmware profile*/
		vivo,fw-id-range-pct = <100>;
		#include "bat_setting/mcu-firmware-data-xh.dtsi"
		#include "bat_setting/mcu-firmware-data-44w-notbus.dtsi"
		#include "bat_setting/mcu-firmware-data-ln8000-notbus.dtsi"
	};

	bq25890h@6a {
		compatible = "ti,bq25890h";
		reg = <0x6a>;

		//vivo,int-gpio = <&pio 11 0>;
	};

	bq25601d@6b {
		compatible = "ti,bq25601d";
		reg = <0x6b>;

		//vivo,int-gpio = <&pio 11 0>;
		vivo,enable-gpio = <&pio 13 0>;
	};

	rt9467@5b {
		compatible = "richtek,rt9467";
		reg = <0x5b>;

		//vivo,int-gpio = <&pio 3 0>;
		//vivo,enable-gpio = <&pio 166 0>;
	};
};
#endif
/* fuxi add for battery&charge end */

/* yangtao add for usb start */
&usb3_tune {
	u2_vrt_ref = <0x7>;
	u2_term_ref = <0x5>;
	u2_enhance = <0x3>;
	u2_vrt_ref_host = <0x5>;
	u2_term_ref_host = <0x5>;
	u2_enhance_host = <0x2>;
};
/* yangtao add for usb end */



/*************************
 * KPD DTSI File
*************************/

&keypad {
	mediatek,kpd-key-debounce = <1024>;
	mediatek,kpd-sw-pwrkey = <116>;
	mediatek,kpd-hw-pwrkey = <8>;
	mediatek,kpd-sw-rstkey  = <114>;
	mediatek,kpd-hw-rstkey = <17>;
	mediatek,kpd-use-extend-type = <0>;
	/*HW Keycode [0~71] -> Linux Keycode*/
	mediatek,kpd-hw-map-num = <72>;
	mediatek,kpd-hw-init-map = <115 0 0 0 0 0 0 0 0 0 0 0 0 0 0 0 0 0 0 0 0 0 0 0 0 0 0 0 0 0 0 0 0 0 0 0 0 0 0 0 0 0 0 0 0 0 0 0 0 0 0 0 0 0 0 0 0 0 0 0 0 0 0 0 0 0 0 0 0 0 0 0 >;
	mediatek,kpd-pwrkey-eint-gpio = <0>;
	mediatek,kpd-pwkey-gpio-din  = <0>;
	mediatek,kpd-hw-dl-key0 = <17>;
	mediatek,kpd-hw-dl-key1 = <0>;
	mediatek,kpd-hw-dl-key2 = <8>;
	mediatek,kpd-hw-recovery-key = <17>;
	mediatek,kpd-hw-factory-key = <0>;
	status = "okay";
};

/*************************
 * WIFI DTSI File
*************************/
&wifi {
	flavor_bin = "c";
};
/*************************
 * BT DTSI File
*************************/
&bt {
	flavor_bin = "c";
};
